# ATmega325P device description
Architecture: AVR8; Family: megaAVR
Registers are 8-bit, access not given, no defined reset value unless marked. A register's access mark holds for its fields unless they carry their own. Offsets are from the block's base; [hi:lo] are bit positions.

## BOOT_LOAD — Bootloader
Instances: BOOT_LOAD 0x00
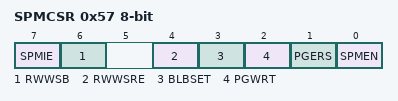
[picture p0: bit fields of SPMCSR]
0x57 SPMCSR — Store Program Memory Control Register
  [7] SPMIE — SPM Interrupt Enable
  [6] RWWSB — Read While Write Section Busy
  [4] RWWSRE — Read While Write section read enable
  [3] BLBSET — Boot Lock Bit Set
  [2] PGWRT — Page Write
  [1] PGERS — Page Erase
  [0] SPMEN — Store Program Memory Enable

## JTAG — JTAG Interface
Instances: JTAG 0x00
0x51 OCDR — On-Chip Debug Related Register in I/O Memory
0x54 MCUSR — MCU Status Register
  [4] JTRF — JTAG Reset Flag
0x55 MCUCR — MCU Control Register
  [7] JTD — JTAG Interface Disable

## EXINT — External Interrupts
Instances: EXINT 0x00
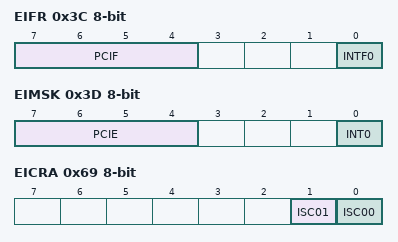
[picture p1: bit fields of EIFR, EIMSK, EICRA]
0x3C EIFR — External Interrupt Flag Register
  [7:4] PCIF — Pin Change Interrupt Flags
  [0] INTF0 — External Interrupt Flag 0
0x3D EIMSK — External Interrupt Mask Register
  [7:4] PCIE — Pin Change Interrupt Enables
  [0] INT0 — External Interrupt Request 0 Enable
0x69 EICRA — External Interrupt Control Register A
  [1] ISC01 — External Interrupt Sense Control 0 Bit 1
  [0] ISC00 — External Interrupt Sense Control 0 Bit 0
    0=Low Level of INTX; 1=Any Logical Change of INTX; 2=Falling Edge of INTX; 3=Rising Edge of INTX
0x6B PCMSK0 — Pin Change Mask Register 0
  [7:0] PCINT — Pin Change Mask bits
0x6C PCMSK1 — Pin Change Mask Register 1
  [7:0] PCINT (bit 8 of the value upward) — Pin Change Mask bits

## EEPROM
Instances: EEPROM 0x00
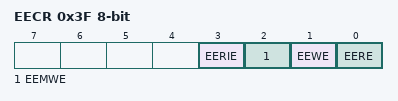
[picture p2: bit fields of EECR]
0x3F EECR — EEPROM Control Register
  [3] EERIE — EEPROM Ready Interrupt Enable
  [2] EEMWE — EEPROM Master Write Enable
  [1] EEWE — EEPROM Write Enable
  [0] EERE — EEPROM Read Enable
0x40 EEDR — EEPROM Data Register
0x41 EEAR 16-bit bits used 9:0 — EEPROM Read/Write Access Bytes

## PORTA — I/O Port
Instances: PORTA 0x00
0x20 PINA — Port A Input Pins
0x21 DDRA — Port A Data Direction Register
0x22 PORTA — Port A Data Register

## PORTB — I/O Port
Instances: PORTB 0x00
0x23 PINB — Port B Input Pins
0x24 DDRB — Port B Data Direction Register
0x25 PORTB — Port B Data Register

## PORTC — I/O Port
Instances: PORTC 0x00
0x26 PINC — Port C Input Pins
0x27 DDRC — Port C Data Direction Register
0x28 PORTC — Port C Data Register

## PORTD — I/O Port
Instances: PORTD 0x00
0x29 PIND — Port D Input Pins
0x2A DDRD — Port D Data Direction Register
0x2B PORTD — Port D Data Register

## PORTE — I/O Port
Instances: PORTE 0x00
0x2C PINE — Input Pins, Port E
0x2D DDRE — Data Direction Register, Port E
0x2E PORTE — Data Register, Port E

## PORTF — I/O Port
Instances: PORTF 0x00
0x2F PINF — Input Pins, Port F
0x30 DDRF — Data Direction Register, Port F
0x31 PORTF — Data Register, Port F

## PORTG — I/O Port
Instances: PORTG 0x00
0x32 PING bits used 5:0 — Port G Input Pins
0x33 DDRG bits used 4:0 — Port G Data Direction Register
0x34 PORTG bits used 4:0 — Port G Data Register

## TC0 (TC8 module) — Timer/Counter, 8-bit
Instances: TC0 0x00
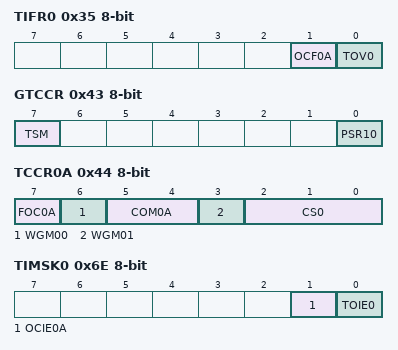
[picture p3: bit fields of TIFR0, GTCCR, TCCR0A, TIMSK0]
0x35 TIFR0 — Timer/Counter0 Interrupt Flag register
  [1] OCF0A — Timer/Counter0 Output Compare Flag 0
  [0] TOV0 — Timer/Counter0 Overflow Flag
0x43 GTCCR — General Timer/Control Register
  [7] TSM — Timer/Counter Synchronization Mode
  [0] PSR10 — Prescaler Reset Timer/Counter1 and Timer/Counter0
0x44 TCCR0A — Timer/Counter0 Control Register
  [7] FOC0A — Force Output Compare
  [6] WGM00 — Waveform Generation Mode 0
    0=Normal; 2=PWM, Phase Correct; 1=CTC; 3=Fast PWM
  [5:4] COM0A — Compare Match Output Modes
  [3] WGM01 — Waveform Generation Mode 1
  [2:0] CS0 — Clock Selects
    0=No Clock Source (Stopped); 1=Running, No Prescaling; 2=Running, CLK/8; 3=Running, CLK/64; 4=Running, CLK/256; 5=Running, CLK/1024; 6=Running, ExtClk Tx Falling Edge; 7=Running, ExtClk Tx Rising Edge
0x46 TCNT0 — Timer/Counter0
0x47 OCR0A — Timer/Counter0 Output Compare Register
0x6E TIMSK0 — Timer/Counter0 Interrupt Mask Register
  [1] OCIE0A — Timer/Counter0 Output Compare Match Interrupt Enable
  [0] TOIE0 — Timer/Counter0 Overflow Interrupt Enable
